# PCIE1_CORE_PCIE_INTD_CFG_INTD_CFG register map
Vendor: Texas Instruments
Peripheral module from a debugger description file (folder J721S2).
Registers are 32-bit, access not given, reset 0x0 unless marked. A register's access mark holds for its fields unless they carry their own. Offsets are as the file gives them; lines under a group give offsets from that group; [hi:lo] are bit positions; {n}, {i} and the like mark numbered series; 'fields as' and 'values as' point back to an identical list; <NAME> marks a mode.

## PCIE1_CORE_PCIE_INTD_CFG_INTD_CFG
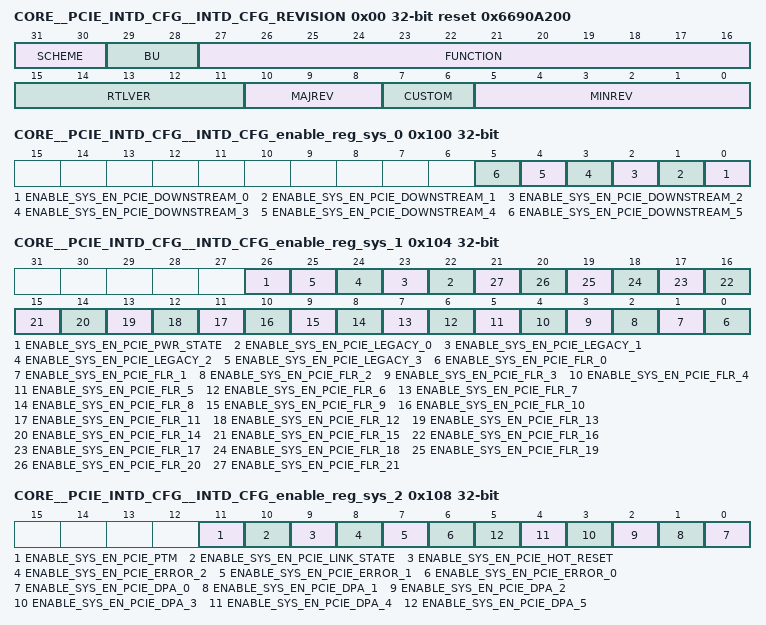
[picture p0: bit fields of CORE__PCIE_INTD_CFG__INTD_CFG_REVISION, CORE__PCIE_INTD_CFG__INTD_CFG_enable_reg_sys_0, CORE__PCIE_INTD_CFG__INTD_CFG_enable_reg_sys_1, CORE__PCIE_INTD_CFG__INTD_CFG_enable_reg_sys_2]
0x00 CORE__PCIE_INTD_CFG__INTD_CFG_REVISION ro reset 0x6690A200 — Revision Register
  [31:30] SCHEME
  [29:28] BU
  [27:16] FUNCTION — Module ID
  [15:11] RTLVER — RTL revisions
  [10:8] MAJREV — Major revision
  [7:6] CUSTOM — Custom revision
  [5:0] MINREV — Minor revision
0x100 CORE__PCIE_INTD_CFG__INTD_CFG_enable_reg_sys_0 — Enable Register 0
  [n] ENABLE_SYS_EN_PCIE_DOWNSTREAM_{n} (n=0..5) — Enable Set for sys_en_pcie_downstream_{n} (access R/W1TS)
0x104 CORE__PCIE_INTD_CFG__INTD_CFG_enable_reg_sys_1 — Enable Register 1
  [26] ENABLE_SYS_EN_PCIE_PWR_STATE — Enable Set for sys_en_pcie_pwr_state (access R/W1TS)
  [n+22] ENABLE_SYS_EN_PCIE_LEGACY_{n} (n=0..3) — Enable Set for sys_en_pcie_legacy_{n} (access R/W1TS)
  [n] ENABLE_SYS_EN_PCIE_FLR_{n} (n=0..21) — Enable Set for sys_en_pcie_flr_{n} (access R/W1TS)
0x108 CORE__PCIE_INTD_CFG__INTD_CFG_enable_reg_sys_2 — Enable Register 2
  [11] ENABLE_SYS_EN_PCIE_PTM — Enable Set for sys_en_pcie_ptm (access R/W1TS)
  [10] ENABLE_SYS_EN_PCIE_LINK_STATE — Enable Set for sys_en_pcie_link_state (access R/W1TS)
  [9] ENABLE_SYS_EN_PCIE_HOT_RESET — Enable Set for sys_en_pcie_hot_reset (access R/W1TS)
  [8] ENABLE_SYS_EN_PCIE_ERROR_2 — Enable Set for sys_en_pcie_error_2 (access R/W1TS)
  [7] ENABLE_SYS_EN_PCIE_ERROR_1 — Enable Set for sys_en_pcie_error_1 (access R/W1TS)
  [6] ENABLE_SYS_EN_PCIE_ERROR_0 — Enable Set for sys_en_pcie_error_0 (access R/W1TS)
  [n] ENABLE_SYS_EN_PCIE_DPA_{n} (n=0..5) — Enable Set for sys_en_pcie_dpa_{n} (access R/W1TS)
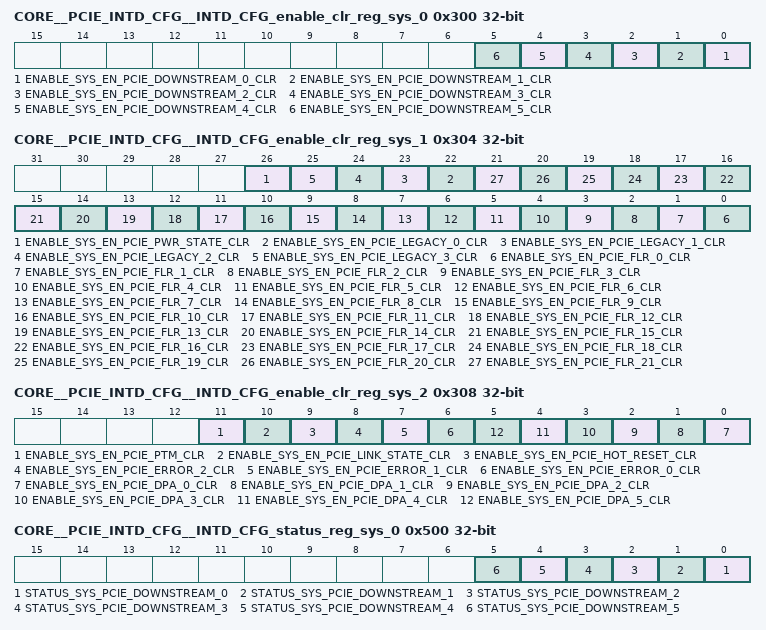
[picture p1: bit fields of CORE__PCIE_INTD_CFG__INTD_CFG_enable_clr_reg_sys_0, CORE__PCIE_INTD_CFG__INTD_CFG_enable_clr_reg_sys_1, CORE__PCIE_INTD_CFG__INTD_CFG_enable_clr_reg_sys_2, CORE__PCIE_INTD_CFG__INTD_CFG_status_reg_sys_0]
0x300 CORE__PCIE_INTD_CFG__INTD_CFG_enable_clr_reg_sys_0 — Enable Clear Register 0
  [n] ENABLE_SYS_EN_PCIE_DOWNSTREAM_{n}_CLR (n=0..5) — Enable Clear for sys_en_pcie_downstream_{n} (access R/W1TC)
0x304 CORE__PCIE_INTD_CFG__INTD_CFG_enable_clr_reg_sys_1 — Enable Clear Register 1
  [26] ENABLE_SYS_EN_PCIE_PWR_STATE_CLR — Enable Clear for sys_en_pcie_pwr_state (access R/W1TC)
  [n+22] ENABLE_SYS_EN_PCIE_LEGACY_{n}_CLR (n=0..3) — Enable Clear for sys_en_pcie_legacy_{n} (access R/W1TC)
  [n] ENABLE_SYS_EN_PCIE_FLR_{n}_CLR (n=0..21) — Enable Clear for sys_en_pcie_flr_{n} (access R/W1TC)
0x308 CORE__PCIE_INTD_CFG__INTD_CFG_enable_clr_reg_sys_2 — Enable Clear Register 2
  [11] ENABLE_SYS_EN_PCIE_PTM_CLR — Enable Clear for sys_en_pcie_ptm (access R/W1TC)
  [10] ENABLE_SYS_EN_PCIE_LINK_STATE_CLR — Enable Clear for sys_en_pcie_link_state (access R/W1TC)
  [9] ENABLE_SYS_EN_PCIE_HOT_RESET_CLR — Enable Clear for sys_en_pcie_hot_reset (access R/W1TC)
  [8] ENABLE_SYS_EN_PCIE_ERROR_2_CLR — Enable Clear for sys_en_pcie_error_2 (access R/W1TC)
  [7] ENABLE_SYS_EN_PCIE_ERROR_1_CLR — Enable Clear for sys_en_pcie_error_1 (access R/W1TC)
  [6] ENABLE_SYS_EN_PCIE_ERROR_0_CLR — Enable Clear for sys_en_pcie_error_0 (access R/W1TC)
  [n] ENABLE_SYS_EN_PCIE_DPA_{n}_CLR (n=0..5) — Enable Clear for sys_en_pcie_dpa_{n} (access R/W1TC)
0x500 CORE__PCIE_INTD_CFG__INTD_CFG_status_reg_sys_0 ro — Status Register 0
  [n] STATUS_SYS_PCIE_DOWNSTREAM_{n} (n=0..5) — Status for sys_en_pcie_downstream_{n}
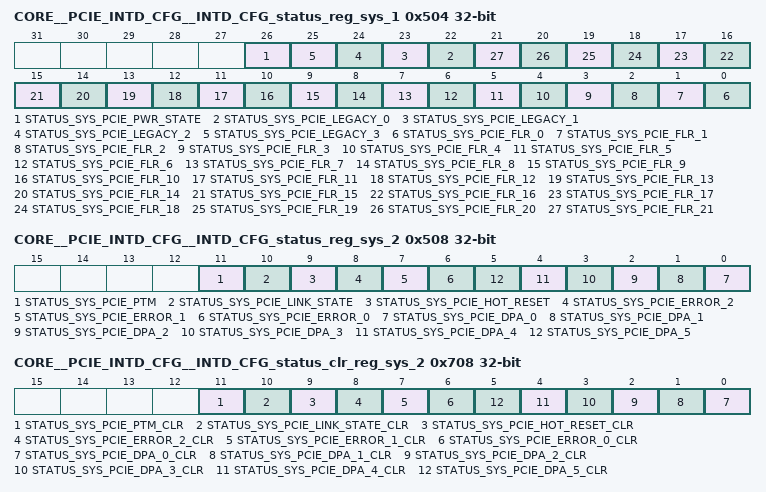
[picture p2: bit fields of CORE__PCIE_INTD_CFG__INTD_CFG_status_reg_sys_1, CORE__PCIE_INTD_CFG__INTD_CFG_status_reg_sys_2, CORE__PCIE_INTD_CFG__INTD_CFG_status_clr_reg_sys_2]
0x504 CORE__PCIE_INTD_CFG__INTD_CFG_status_reg_sys_1 ro — Status Register 1
  [26] STATUS_SYS_PCIE_PWR_STATE — Status for sys_en_pcie_pwr_state
  [n+22] STATUS_SYS_PCIE_LEGACY_{n} (n=0..3) — Status for sys_en_pcie_legacy_{n}
  [n] STATUS_SYS_PCIE_FLR_{n} (n=0..21) — Status for sys_en_pcie_flr_{n}
0x508 CORE__PCIE_INTD_CFG__INTD_CFG_status_reg_sys_2 — Status Register 2
  [11] STATUS_SYS_PCIE_PTM — Status ,write 1 to set, for sys_en_pcie_ptm (access R/W1TS)
  [10] STATUS_SYS_PCIE_LINK_STATE — Status ,write 1 to set, for sys_en_pcie_link_state (access R/W1TS)
  [9] STATUS_SYS_PCIE_HOT_RESET — Status ,write 1 to set, for sys_en_pcie_hot_reset (access R/W1TS)
  [8] STATUS_SYS_PCIE_ERROR_2 — Status ,write 1 to set, for sys_en_pcie_error_2 (access R/W1TS)
  [7] STATUS_SYS_PCIE_ERROR_1 — Status ,write 1 to set, for sys_en_pcie_error_1 (access R/W1TS)
  [6] STATUS_SYS_PCIE_ERROR_0 — Status ,write 1 to set, for sys_en_pcie_error_0 (access R/W1TS)
  [n] STATUS_SYS_PCIE_DPA_{n} (n=0..5) — Status ,write 1 to set, for sys_en_pcie_dpa_{n} (access R/W1TS)
0x708 CORE__PCIE_INTD_CFG__INTD_CFG_status_clr_reg_sys_2 — Status Clear Register 2
  [11] STATUS_SYS_PCIE_PTM_CLR — Status ,write 1 to clear, for sys_en_pcie_ptm (access R/W1TC)
  [10] STATUS_SYS_PCIE_LINK_STATE_CLR — Status ,write 1 to clear, for sys_en_pcie_link_state (access R/W1TC)
  [9] STATUS_SYS_PCIE_HOT_RESET_CLR — Status ,write 1 to clear, for sys_en_pcie_hot_reset (access R/W1TC)
  [8] STATUS_SYS_PCIE_ERROR_2_CLR — Status ,write 1 to clear, for sys_en_pcie_error_2 (access R/W1TC)
  [7] STATUS_SYS_PCIE_ERROR_1_CLR — Status ,write 1 to clear, for sys_en_pcie_error_1 (access R/W1TC)
  [6] STATUS_SYS_PCIE_ERROR_0_CLR — Status ,write 1 to clear, for sys_en_pcie_error_0 (access R/W1TC)
  [n] STATUS_SYS_PCIE_DPA_{n}_CLR (n=0..5) — Status ,write 1 to clear, for sys_en_pcie_dpa_{n} (access R/W1TC)
0xA80 CORE__PCIE_INTD_CFG__INTD_CFG_intr_vector_reg_sys ro — Interrupt Vector for sys
  [31:0] INTR_VECTOR_SYS — Interrupt Vector
